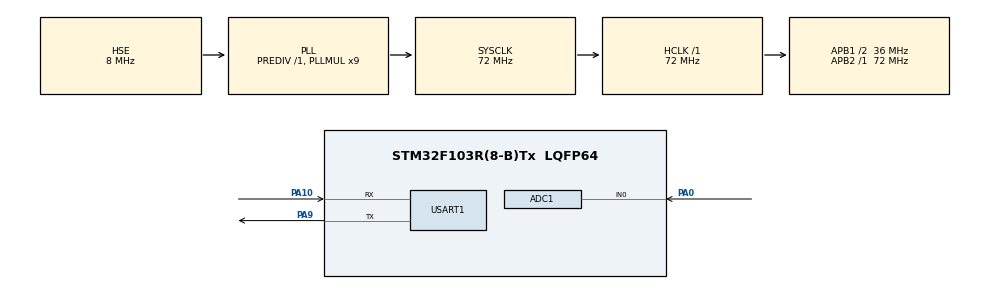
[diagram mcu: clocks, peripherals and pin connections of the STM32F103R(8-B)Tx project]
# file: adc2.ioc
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ADC1.Channel-1\#ChannelRegularConversion=ADC_CHANNEL_0
ADC1.ContinuousConvMode=ENABLE
ADC1.ExternalTrigConv=ADC_SOFTWARE_START
ADC1.NbrOfConversionFlag=1
ADC1.Rank-1\#ChannelRegularConversion=1
ADC1.SamplingTime-1\#ChannelRegularConversion=ADC_SAMPLETIME_71CYCLES_5
ADC1.master=1
Dma.ADC1.1.Direction=DMA_PERIPH_TO_MEMORY
Dma.ADC1.1.Instance=DMA1_Channel1
Dma.ADC1.1.MemDataAlignment=DMA_MDATAALIGN_HALFWORD
Dma.ADC1.1.MemInc=DMA_MINC_ENABLE
Dma.ADC1.1.Mode=DMA_CIRCULAR
Dma.ADC1.1.PeriphDataAlignment=DMA_PDATAALIGN_HALFWORD
Dma.ADC1.1.PeriphInc=DMA_PINC_DISABLE
Dma.ADC1.1.Priority=DMA_PRIORITY_LOW
Dma.Request0=USART1_RX
Dma.Request1=ADC1
Dma.USART1_RX.0.Direction=DMA_PERIPH_TO_MEMORY
Dma.USART1_RX.0.Instance=DMA1_Channel5
Dma.USART1_RX.0.MemDataAlignment=DMA_MDATAALIGN_BYTE
Dma.USART1_RX.0.MemInc=DMA_MINC_ENABLE
Dma.USART1_RX.0.Mode=DMA_NORMAL
Dma.USART1_RX.0.PeriphDataAlignment=DMA_PDATAALIGN_BYTE
Dma.USART1_RX.0.PeriphInc=DMA_PINC_DISABLE
Dma.USART1_RX.0.Priority=DMA_PRIORITY_LOW
Mcu.Family=STM32F1
Mcu.Name=STM32F103R(8-B)Tx
Mcu.Package=LQFP64
NVIC.DMA1_Channel1_IRQn=true\:0\:0\:false\:false\:true\:false\:true\:true
NVIC.DMA1_Channel5_IRQn=true\:0\:0\:false\:false\:true\:false\:true\:true
NVIC.PriorityGroup=NVIC_PRIORITYGROUP_4
PA0-WKUP.Signal=ADCx_IN0
PA10.Mode=Asynchronous
PA10.Signal=USART1_RX
PA13.Mode=Serial_Wire
PA13.Signal=SYS_JTMS-SWDIO
PA14.Mode=Serial_Wire
PA14.Signal=SYS_JTCK-SWCLK
PA9.Mode=Asynchronous
PA9.Signal=USART1_TX
PD0-OSC_IN.Mode=HSE-External-Oscillator
PD0-OSC_IN.Signal=RCC_OSC_IN
PD1-OSC_OUT.Mode=HSE-External-Oscillator
PD1-OSC_OUT.Signal=RCC_OSC_OUT
ProjectManager.HeapSize=0x200
ProjectManager.StackSize=0x400
ProjectManager.TargetToolchain=STM32CubeIDE
RCC.ADCPresc=RCC_ADCPCLK2_DIV6
RCC.AHBFreq_Value=72000000
RCC.APB1CLKDivider=RCC_HCLK_DIV2
RCC.APB1Freq_Value=36000000
RCC.APB1TimFreq_Value=72000000
RCC.APB2Freq_Value=72000000
RCC.APB2TimFreq_Value=72000000
RCC.HCLKFreq_Value=72000000
RCC.PLLMUL=RCC_PLL_MUL9
RCC.PLLSourceVirtual=RCC_PLLSOURCE_HSE
RCC.SYSCLKFreq_VALUE=72000000
RCC.SYSCLKSource=RCC_SYSCLKSOURCE_PLLCLK
RCC.USBFreq_Value=72000000
SH.ADCx_IN0.0=ADC1_IN0,IN0
USART1.VirtualMode=VM_ASYNC
board=custom

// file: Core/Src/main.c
/* USER CODE BEGIN Header */
/**
  ******************************************************************************
  * @file           : main.c
  * @brief          : Main program body
  ******************************************************************************
  * @attention
  *
  * Copyright (c) 2024 STMicroelectronics.
  * All rights reserved.
  *
  * This software is licensed under terms that can be found in the LICENSE file
  * in the root directory of this software component.
  * If no LICENSE file comes with this software, it is provided AS-IS.
  *
  ******************************************************************************
  */
/* USER CODE END Header */
#include "main.h"
#include "adc.h"
#include "dma.h"
#include "usart.h"
#include "gpio.h"

/* USER CODE BEGIN Includes */
#include <stdio.h>
/* USER CODE END Includes */

void SystemClock_Config(void);
/* USER CODE BEGIN PFP */
int __io_putchar(int ch){
	HAL_UART_Transmit(&huart1,(uint8_t *)&ch,1,100);
	return 0;
}

uint8_t print_voltage_val(uint32_t _12_bit_resolution,uint32_t resolution,float ref_voltage){
	uint32_t a = _12_bit_resolution;
	printf("voltage val : ");
	a = (uint32_t)(a+1)*1000/resolution;
	a = a * ref_voltage;
	uint32_t b = a/1000;
	printf("%lu.%03lu\n",a/1000,a-b*1000);
	return (uint8_t)a/1000;
}
/* USER CODE END PFP */

int main(void)
{

  /* MCU Configuration--------------------------------------------------------*/

  /* Reset of all peripherals, Initializes the Flash interface and the Systick. */
  HAL_Init();

  /* Configure the system clock */
  SystemClock_Config();

  /* Initialize all configured peripherals */
  MX_GPIO_Init();
  MX_DMA_Init();
  MX_ADC1_Init();
  MX_USART1_UART_Init();
  /* USER CODE BEGIN 2 */
  uint32_t adc_val=0;
  HAL_ADC_Start_DMA(&hadc1,&adc_val,1);
  /* USER CODE END 2 */

  /* Infinite loop */
  /* USER CODE BEGIN WHILE */
  while (1)
  {
	  printf("%lu\n",adc_val);
	  print_voltage_val(adc_val,4096,3.3);
	  HAL_Delay(100);
    /* USER CODE END WHILE */

  }
}

void SystemClock_Config(void)
{
  RCC_OscInitTypeDef RCC_OscInitStruct = {0};
  RCC_ClkInitTypeDef RCC_ClkInitStruct = {0};
  RCC_PeriphCLKInitTypeDef PeriphClkInit = {0};

  /** Initializes the RCC Oscillators according to the specified parameters
  * in the RCC_OscInitTypeDef structure.
  */
  RCC_OscInitStruct.OscillatorType = RCC_OSCILLATORTYPE_HSE;
  RCC_OscInitStruct.HSEState = RCC_HSE_ON;
  RCC_OscInitStruct.HSEPredivValue = RCC_HSE_PREDIV_DIV1;
  RCC_OscInitStruct.HSIState = RCC_HSI_ON;
  RCC_OscInitStruct.PLL.PLLState = RCC_PLL_ON;
  RCC_OscInitStruct.PLL.PLLSource = RCC_PLLSOURCE_HSE;
  RCC_OscInitStruct.PLL.PLLMUL = RCC_PLL_MUL9;
  if (HAL_RCC_OscConfig(&RCC_OscInitStruct) != HAL_OK)
  {
    Error_Handler();
  }

  /** Initializes the CPU, AHB and APB buses clocks
  */
  RCC_ClkInitStruct.ClockType = RCC_CLOCKTYPE_HCLK|RCC_CLOCKTYPE_SYSCLK
                              |RCC_CLOCKTYPE_PCLK1|RCC_CLOCKTYPE_PCLK2;
  RCC_ClkInitStruct.SYSCLKSource = RCC_SYSCLKSOURCE_PLLCLK;
  RCC_ClkInitStruct.AHBCLKDivider = RCC_SYSCLK_DIV1;
  RCC_ClkInitStruct.APB1CLKDivider = RCC_HCLK_DIV2;
  RCC_ClkInitStruct.APB2CLKDivider = RCC_HCLK_DIV1;

  if (HAL_RCC_ClockConfig(&RCC_ClkInitStruct, FLASH_LATENCY_2) != HAL_OK)
  {
    Error_Handler();
  }
  PeriphClkInit.PeriphClockSelection = RCC_PERIPHCLK_ADC;
  PeriphClkInit.AdcClockSelection = RCC_ADCPCLK2_DIV6;
  if (HAL_RCCEx_PeriphCLKConfig(&PeriphClkInit) != HAL_OK)
  {
    Error_Handler();
  }
}

void Error_Handler(void)
{
  __disable_irq();
  while (1)
  {
  }
}
